# R9A09G057H register map
Vendor: Renesas Electronics; File version: 1.0
Registers are 32-bit, read-write, no defined reset value unless marked. A register's access mark holds for its fields unless they carry their own. Offsets are from the block's base; [hi:lo] are bit positions; {n}, {i} and the like mark numbered series.

## R_GPT0 — IO define file for gpt.
Base 0x13010000
Same registers: R_GPT1 0x13010100, R_GPT2 0x13010200, R_GPT3 0x13010300, R_GPT4 0x13010400, R_GPT5 0x13010500, R_GPT6 0x13010600, R_GPT7 0x13010700, R_GPT{n} {0x1301F600+0x100*n} (n=10..17)
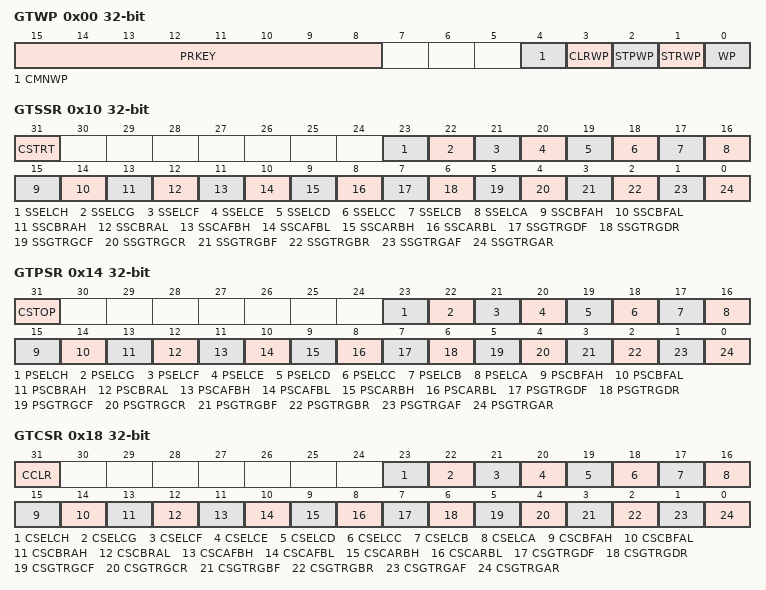
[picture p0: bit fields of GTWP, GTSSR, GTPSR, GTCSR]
0x00 GTWP
  [15:8] PRKEY wo, [4] CMNWP, [3] CLRWP, [2] STPWP, [1] STRWP, [0] WP
0x04 GTSTR
  [31:0] CSTRT
0x08 GTSTP
  [31:0] CSTOP
0x0C GTCLR wo
  [31:0] CCLR
0x10 GTSSR
  [31] CSTRT, [23] SSELCH, [22] SSELCG, [21] SSELCF, [20] SSELCE, [19] SSELCD, [18] SSELCC, [17] SSELCB, [16] SSELCA, [15] SSCBFAH, [14] SSCBFAL, [13] SSCBRAH, [12] SSCBRAL, [11] SSCAFBH, [10] SSCAFBL, [9] SSCARBH, [8] SSCARBL, [7] SSGTRGDF, [6] SSGTRGDR, [5] SSGTRGCF, [4] SSGTRGCR, [3] SSGTRGBF, [2] SSGTRGBR, [1] SSGTRGAF, [0] SSGTRGAR
0x14 GTPSR
  [31] CSTOP, [23] PSELCH, [22] PSELCG, [21] PSELCF, [20] PSELCE, [19] PSELCD, [18] PSELCC, [17] PSELCB, [16] PSELCA, [15] PSCBFAH, [14] PSCBFAL, [13] PSCBRAH, [12] PSCBRAL, [11] PSCAFBH, [10] PSCAFBL, [9] PSCARBH, [8] PSCARBL, [7] PSGTRGDF, [6] PSGTRGDR, [5] PSGTRGCF, [4] PSGTRGCR, [3] PSGTRGBF, [2] PSGTRGBR, [1] PSGTRGAF, [0] PSGTRGAR
0x18 GTCSR
  [31] CCLR, [23] CSELCH, [22] CSELCG, [21] CSELCF, [20] CSELCE, [19] CSELCD, [18] CSELCC, [17] CSELCB, [16] CSELCA, [15] CSCBFAH, [14] CSCBFAL, [13] CSCBRAH, [12] CSCBRAL, [11] CSCAFBH, [10] CSCAFBL, [9] CSCARBH, [8] CSCARBL, [7] CSGTRGDF, [6] CSGTRGDR, [5] CSGTRGCF, [4] CSGTRGCR, [3] CSGTRGBF, [2] CSGTRGBR, [1] CSGTRGAF, [0] CSGTRGAR
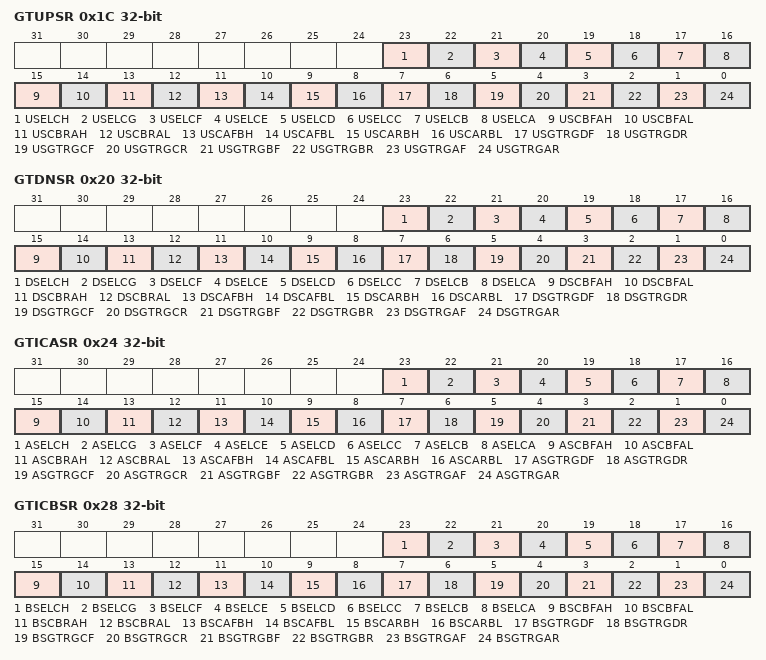
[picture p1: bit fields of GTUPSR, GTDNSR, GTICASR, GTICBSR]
0x1C GTUPSR
  [23] USELCH, [22] USELCG, [21] USELCF, [20] USELCE, [19] USELCD, [18] USELCC, [17] USELCB, [16] USELCA, [15] USCBFAH, [14] USCBFAL, [13] USCBRAH, [12] USCBRAL, [11] USCAFBH, [10] USCAFBL, [9] USCARBH, [8] USCARBL, [7] USGTRGDF, [6] USGTRGDR, [5] USGTRGCF, [4] USGTRGCR, [3] USGTRGBF, [2] USGTRGBR, [1] USGTRGAF, [0] USGTRGAR
0x20 GTDNSR
  [23] DSELCH, [22] DSELCG, [21] DSELCF, [20] DSELCE, [19] DSELCD, [18] DSELCC, [17] DSELCB, [16] DSELCA, [15] DSCBFAH, [14] DSCBFAL, [13] DSCBRAH, [12] DSCBRAL, [11] DSCAFBH, [10] DSCAFBL, [9] DSCARBH, [8] DSCARBL, [7] DSGTRGDF, [6] DSGTRGDR, [5] DSGTRGCF, [4] DSGTRGCR, [3] DSGTRGBF, [2] DSGTRGBR, [1] DSGTRGAF, [0] DSGTRGAR
0x24 GTICASR
  [23] ASELCH, [22] ASELCG, [21] ASELCF, [20] ASELCE, [19] ASELCD, [18] ASELCC, [17] ASELCB, [16] ASELCA, [15] ASCBFAH, [14] ASCBFAL, [13] ASCBRAH, [12] ASCBRAL, [11] ASCAFBH, [10] ASCAFBL, [9] ASCARBH, [8] ASCARBL, [7] ASGTRGDF, [6] ASGTRGDR, [5] ASGTRGCF, [4] ASGTRGCR, [3] ASGTRGBF, [2] ASGTRGBR, [1] ASGTRGAF, [0] ASGTRGAR
0x28 GTICBSR
  [23] BSELCH, [22] BSELCG, [21] BSELCF, [20] BSELCE, [19] BSELCD, [18] BSELCC, [17] BSELCB, [16] BSELCA, [15] BSCBFAH, [14] BSCBFAL, [13] BSCBRAH, [12] BSCBRAL, [11] BSCAFBH, [10] BSCAFBL, [9] BSCARBH, [8] BSCARBL, [7] BSGTRGDF, [6] BSGTRGDR, [5] BSGTRGCF, [4] BSGTRGCR, [3] BSGTRGBF, [2] BSGTRGBR, [1] BSGTRGAF, [0] BSGTRGAR
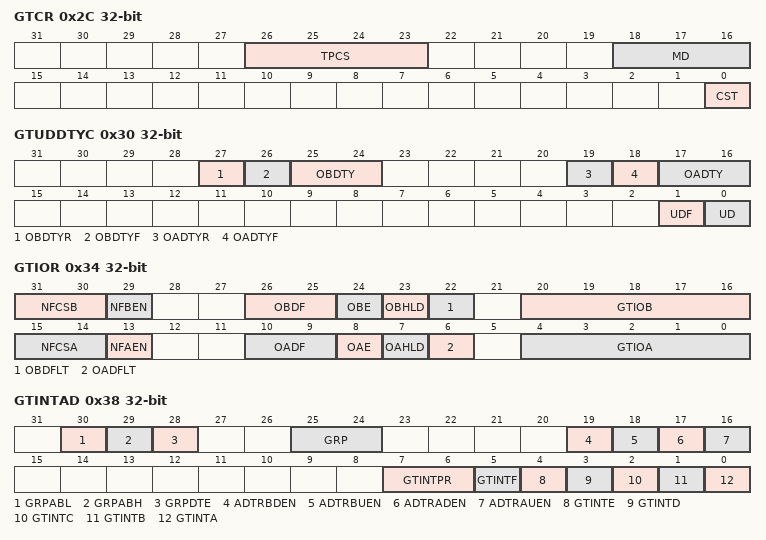
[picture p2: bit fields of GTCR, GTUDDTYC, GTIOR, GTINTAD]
0x2C GTCR
  [26:23] TPCS, [18:16] MD, [0] CST
0x30 GTUDDTYC
  [27] OBDTYR, [26] OBDTYF, [25:24] OBDTY, [19] OADTYR, [18] OADTYF, [17:16] OADTY, [1] UDF, [0] UD
0x34 GTIOR
  [31:30] NFCSB, [29] NFBEN, [26:25] OBDF, [24] OBE, [23] OBHLD, [22] OBDFLT, [20:16] GTIOB, [15:14] NFCSA, [13] NFAEN, [10:9] OADF, [8] OAE, [7] OAHLD, [6] OADFLT, [4:0] GTIOA
0x38 GTINTAD
  [30] GRPABL, [29] GRPABH, [28] GRPDTE, [25:24] GRP, [19] ADTRBDEN, [18] ADTRBUEN, [17] ADTRADEN, [16] ADTRAUEN, [7:6] GTINTPR, [5] GTINTF, [4] GTINTE, [3] GTINTD, [2] GTINTC, [1] GTINTB, [0] GTINTA
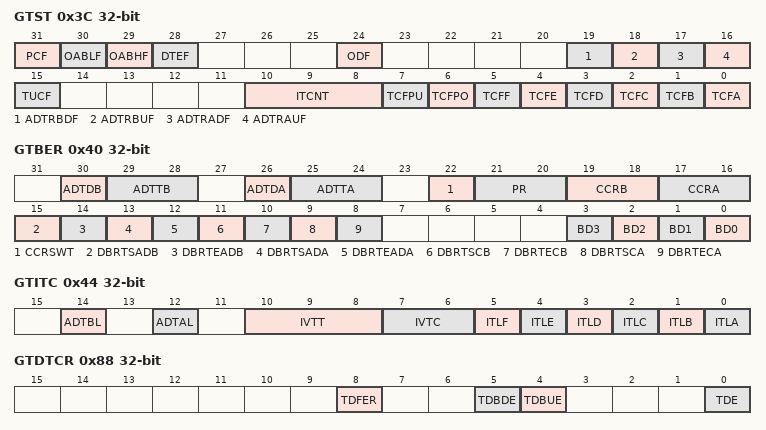
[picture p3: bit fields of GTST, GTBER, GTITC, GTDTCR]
0x3C GTST
  [31] PCF, [30] OABLF ro, [29] OABHF ro, [28] DTEF ro, [24] ODF ro, [19] ADTRBDF, [18] ADTRBUF, [17] ADTRADF, [16] ADTRAUF, [15] TUCF ro, [10:8] ITCNT ro, [7] TCFPU, [6] TCFPO, [5] TCFF, [4] TCFE, [3] TCFD, [2] TCFC, [1] TCFB, [0] TCFA
0x40 GTBER
  [30] ADTDB, [29:28] ADTTB, [26] ADTDA, [25:24] ADTTA, [22] CCRSWT wo, [21:20] PR, [19:18] CCRB, [17:16] CCRA, [15] DBRTSADB, [14] DBRTEADB, [13] DBRTSADA, [12] DBRTEADA, [11] DBRTSCB, [10] DBRTECB, [9] DBRTSCA, [8] DBRTECA, [n] BD{n} (n=0..3)
0x44 GTITC
  [14] ADTBL, [12] ADTAL, [10:8] IVTT, [7:6] IVTC, [5] ITLF, [4] ITLE, [3] ITLD, [2] ITLC, [1] ITLB, [0] ITLA
0x48 GTCNT
0x4C GTCCRA
  [31:0] GTCCR
0x50 GTCCRB
  [31:0] GTCCR
0x54 GTCCRC
  [31:0] GTCCR
0x58 GTCCRE
  [31:0] GTCCR
0x5C GTCCRD
  [31:0] GTCCR
0x60 GTCCRF
  [31:0] GTCCR
0x64 GTPR
0x68 GTPBR
0x6C GTPDBR
0x70 GTADTRA
  [31:0] GTADTR
0x74 GTADTBRA
  [31:0] GTADTBR
0x78 GTADTDBRA
  [31:0] GTADTDBR
0x7C GTADTRB
  [31:0] GTADTR
0x80 GTADTBRB
  [31:0] GTADTBR
0x84 GTADTDBRB
  [31:0] GTADTDBR
0x88 GTDTCR
  [8] TDFER, [5] TDBDE, [4] TDBUE, [0] TDE
0x8C GTDVU
  [31:0] GTDV
0x90 GTDVD
  [31:0] GTDV
0x94 GTDBU
  [31:0] GTDB
0x98 GTDBB
  [31:0] GTDB
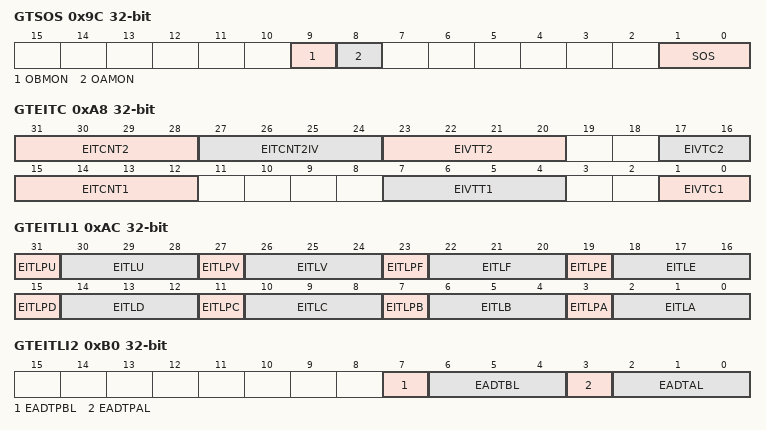
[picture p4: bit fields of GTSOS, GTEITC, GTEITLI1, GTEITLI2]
0x9C GTSOS ro
  [9] OBMON, [8] OAMON, [1:0] SOS
0xA0 GTSOTR
  [0] SOTR
0xA8 GTEITC
  [31:28] EITCNT2 ro, [27:24] EITCNT2IV, [23:20] EIVTT2, [17:16] EIVTC2, [15:12] EITCNT1 ro, [7:4] EIVTT1, [1:0] EIVTC1
0xAC GTEITLI1
  [31] EITLPU, [30:28] EITLU, [27] EITLPV, [26:24] EITLV, [23] EITLPF, [22:20] EITLF, [19] EITLPE, [18:16] EITLE, [15] EITLPD, [14:12] EITLD, [11] EITLPC, [10:8] EITLC, [7] EITLPB, [6:4] EITLB, [3] EITLPA, [2:0] EITLA
0xB0 GTEITLI2
  [7] EADTPBL, [6:4] EADTBL, [3] EADTPAL, [2:0] EADTAL
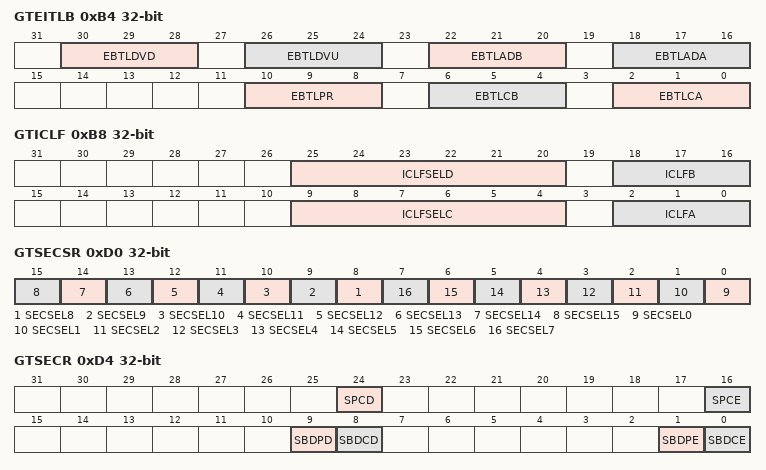
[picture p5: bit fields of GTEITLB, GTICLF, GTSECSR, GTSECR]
0xB4 GTEITLB
  [30:28] EBTLDVD, [26:24] EBTLDVU, [22:20] EBTLADB, [18:16] EBTLADA, [10:8] EBTLPR, [6:4] EBTLCB, [2:0] EBTLCA
0xB8 GTICLF
  [25:20] ICLFSELD, [18:16] ICLFB, [9:4] ICLFSELC, [2:0] ICLFA
0xD0 GTSECSR
  [n] SECSEL{n} ro (n=8..15), [n] SECSEL{n} (n=0..7)
0xD4 GTSECR
  [24] SPCD, [16] SPCE, [9] SBDPD, [8] SBDCD, [1] SBDPE, [0] SBDCE
